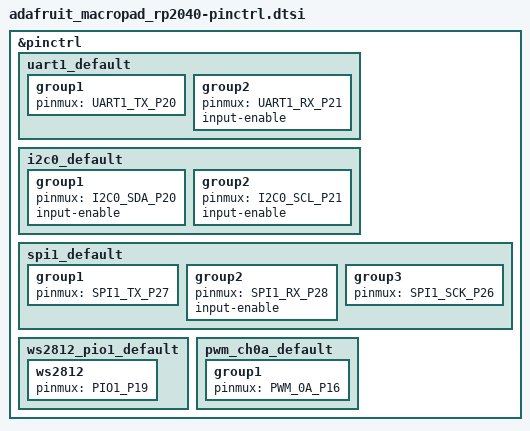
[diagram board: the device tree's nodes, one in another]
#include <dt-bindings/pinctrl/rpi-pico-rp2040-pinctrl.h>

&pinctrl {
	uart1_default: uart1_default {
		group1 {
			pinmux = <UART1_TX_P20>;
		};
		group2 {
			pinmux = <UART1_RX_P21>;
			input-enable;
		};
	};

	i2c0_default: i2c0_default {
		group1 {
			pinmux = <I2C0_SDA_P20>;
			input-enable;
		};
		group2 {
			pinmux = <I2C0_SCL_P21>;
			input-enable;
		};
	};

	spi1_default: spi1_default {
		group1 {
			pinmux = <SPI1_TX_P27>;
		};
		group2 {
			pinmux = <SPI1_RX_P28>;
			input-enable;
		};
		group3 {
			pinmux = <SPI1_SCK_P26>;
		};
	};

	ws2812_pio1_default: ws2812_pio1_default {
		ws2812 {
			pinmux = <PIO1_P19>;
		};
	};

	pwm_ch0a_default: pwm_ch0a_default {
		group1 {
			pinmux = <PWM_0A_P16>;
		};
	};
};
